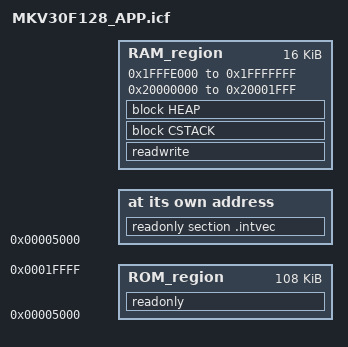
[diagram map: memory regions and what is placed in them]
/* Brogrammer：Application 的链接器配置文件 (MKV30F128_APP.icf) */
/* 目标：程序占用 Flash 0x00005000 - 0x0001FFFF */

/*-Memory Regions-*/
/* 关键修改：将 ROM 区域的起始和结束地址调整为 APP 空间 */
define symbol __ICFEDIT_region_ROM_start__ = 0x00005000; /* <-- App 起始地址 */
define symbol __ICFEDIT_region_ROM_end__   = 0x0001FFFF; /* <-- App 结束地址 (128KB) */
define symbol __ICFEDIT_intvec_start__     = 0x00005000; /* <-- App 向量表起始地址 */

/* RAM 区域保持不变 */
define symbol __ICFEDIT_region_RAM_start__ = 0x1fffe000;
define symbol __ICFEDIT_region_RAM_end__   = 0x1fffffff;
define symbol __region_RAM2_start__ 		= 0x20000000;
define symbol __region_RAM2_end__ 		= 0x20001fff;

/*-Sizes-*/
/* App 的栈和堆使用模板默认值或根据实际需求调整 */
define symbol __ICFEDIT_size_cstack__ = 0x400;
define symbol __ICFEDIT_size_heap__   = 0x800;


/* --- 以下为放置规则，基于你的模板 --- */

define memory mem with size = 4G;

/* 定义 ROM 区域。App 区域是连续的，不需要为 FlashConfig 等低地址区域挖洞 */
define region ROM_region = mem:[from __ICFEDIT_region_ROM_start__ to __ICFEDIT_region_ROM_end__];

/* 定义 RAM 区域，合并两个不连续的块 */
define region RAM_region = mem:[from __ICFEDIT_region_RAM_start__ to __ICFEDIT_region_RAM_end__] | mem:[from __region_RAM2_start__ to __region_RAM2_end__];

define block CSTACK    with alignment = 8, size = __ICFEDIT_size_cstack__   { };
define block HEAP      with alignment = 8, size = __ICFEDIT_size_heap__     { };

initialize by copy { readwrite };
do not initialize  { section .noinit };

/* --- 放置规则 --- */

/* 1. 向量表放在 APP 的 ROM 起始地址 */
place at address mem:__ICFEDIT_intvec_start__ { readonly section .intvec };

/* 2. 关键！App 不应再定义或放置 FlashConfig 段，将其注释掉 */
/* place in FlashConfig_region {section FlashConfig}; */

/* 3. 其他只读数据放在 ROM 区域 */
place in ROM_region   { readonly };

/* 4. 可读写数据、栈、堆放在 RAM 区域 */
place in RAM_region   { readwrite, block CSTACK, block HEAP };
